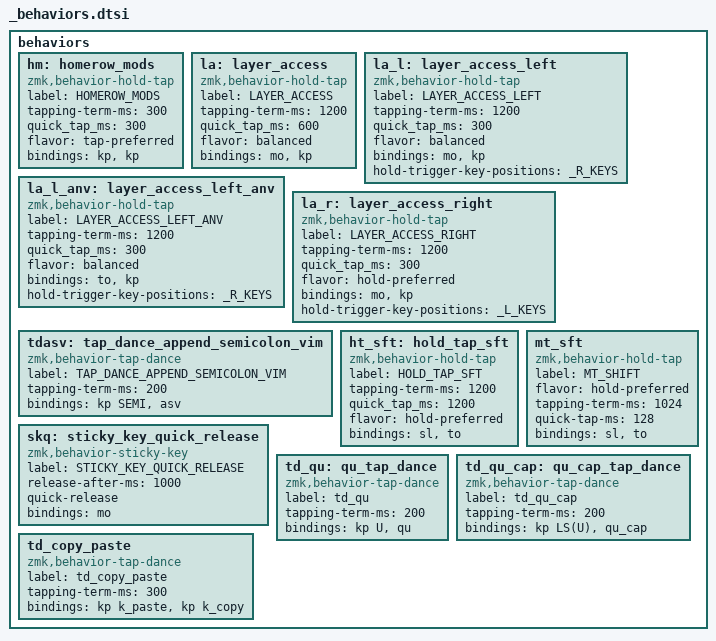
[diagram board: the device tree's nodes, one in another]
#ifndef HEADER
#define HEADER
#include "keymap.h"
#endif

    behaviors {
        hm: homerow_mods {
            compatible = "zmk,behavior-hold-tap";
            label = "HOMEROW_MODS";
            #binding-cells = <2>;
            tapping-term-ms = <300>;
            quick_tap_ms = <300>;
            flavor = "tap-preferred";
            bindings = <&kp>, <&kp>;
        };
        
        la: layer_access {
            compatible = "zmk,behavior-hold-tap";
            label = "LAYER_ACCESS";
            #binding-cells = <2>;
            tapping-term-ms = <1200>;
            quick_tap_ms = <600>;
            flavor = "balanced";
            bindings = <&mo>, <&kp>;
        };

        la_l: layer_access_left {
            compatible = "zmk,behavior-hold-tap";
            label = "LAYER_ACCESS_LEFT";
            #binding-cells = <2>;
            tapping-term-ms = <1200>;
            quick_tap_ms = <300>;
            flavor = "balanced";
            bindings = <&mo>, <&kp>;
            hold-trigger-key-positions = <_R_KEYS>;
        };

        la_l_anv: layer_access_left_anv {
            compatible = "zmk,behavior-hold-tap";
            label = "LAYER_ACCESS_LEFT_ANV";
            #binding-cells = <2>;
            tapping-term-ms = <1200>;
            quick_tap_ms = <300>;
            flavor = "balanced";
            bindings = <&to>, <&kp>;
            hold-trigger-key-positions = <_R_KEYS>;
        };

        la_r: layer_access_right {
            compatible = "zmk,behavior-hold-tap";
            label = "LAYER_ACCESS_RIGHT";
            #binding-cells = <2>;
            tapping-term-ms = <1200>;
            quick_tap_ms = <300>;
            flavor = "hold-preferred";
            bindings = <&mo>, <&kp>;
            hold-trigger-key-positions = <_L_KEYS>;
        };

        tdasv: tap_dance_append_semicolon_vim {
            compatible = "zmk,behavior-tap-dance";
            label = "TAP_DANCE_APPEND_SEMICOLON_VIM";
            #binding-cells = <0>;
            tapping-term-ms = <200>;
            bindings = <&kp SEMI>, <&asv>;
        };

        ht_sft: hold_tap_sft {
            compatible = "zmk,behavior-hold-tap";
            label = "HOLD_TAP_SFT";
            #binding-cells = <2>;
            tapping-term-ms = <1200>;
            quick_tap_ms = <1200>;
            flavor = "hold-preferred";
            bindings = <&sl>, <&to>;
        };

      skq: sticky_key_quick_release {
        compatible = "zmk,behavior-sticky-key";
        label = "STICKY_KEY_QUICK_RELEASE";
        release-after-ms = <1000>;
        quick-release;
        #binding-cells = <1>;
        bindings = <&mo>;
      };

/*
      sl_test: sl_test {
        compatible = "zmk,behavior-sticky-layer";
        label = "SL_TEST";
        release-after-ms = <10>;
        quick-release;
        #binding-cells = <1>;
      };
*/

    mt_sft: mt_sft {
         compatible = "zmk,behavior-hold-tap";
         label = "MT_SHIFT";
         #binding-cells = <2>;
         flavor = "hold-preferred";
         tapping-term-ms = <1024>;
         quick-tap-ms = <128>;
         bindings = <&sl>, <&to>;
    };
    
    td_qu: qu_tap_dance {
        compatible = "zmk,behavior-tap-dance";
        label = "td_qu";
        #binding-cells = <0>;
        tapping-term-ms = <200>;
        bindings = <&kp U>, <&qu>;
    };

    td_qu_cap: qu_cap_tap_dance {
        compatible = "zmk,behavior-tap-dance";
        label = "td_qu_cap";
        #binding-cells = <0>;
        tapping-term-ms = <200>;
        bindings = <&kp LS(U)>, <&qu_cap>;
    };

    td_copy_paste: td_copy_paste {
        compatible = "zmk,behavior-tap-dance";
        label = "td_copy_paste";
        #binding-cells = <0>;
        tapping-term-ms = <300>;
        //bindings = <&ctrl_v>, <&ctrl_c>;
        bindings = <&kp k_paste>, <&kp k_copy>;
    };


         /*
      slq: sticky_layer_quick_release {
        compatible = "zmk,behavior-sticky-layer";
        label = "STICKY_KEY_QUICK_RELEASE";
        #binding-cells = <1>;
        bindings = <&sl>;
        release-after-ms = <1000>;
        quick-release;
      };
*/

    };

/*
    td: td {
        compatible = "zmk,behavior-tap-dance";
        label = "tdlabel";
        #binding-cells = <0>;
        tapping-term-ms = <200>;
        bindings = <&kp A>, <&kp A>;
    };

*/
